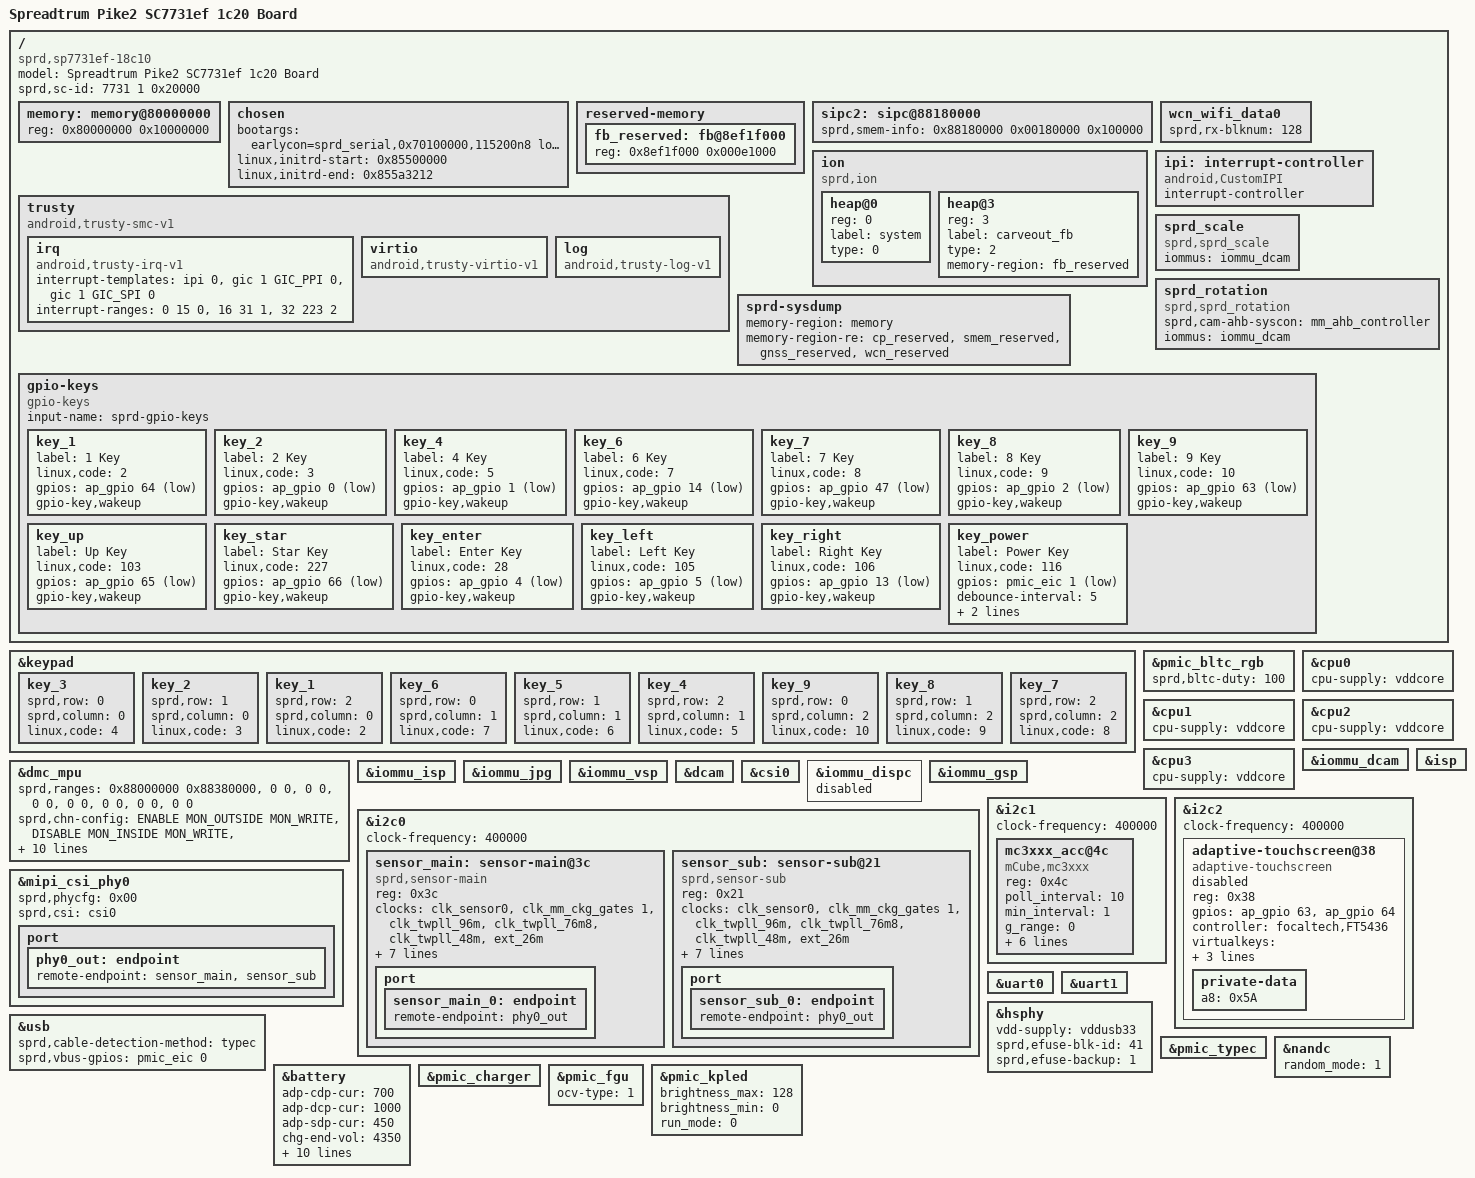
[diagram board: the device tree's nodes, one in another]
/*
 * Spreadtrum Pike2 SP7731ef DTS file
 *
 * Copyright (C) 2016-2017, Spreadtrum Communications Inc.
 *
 * This file is licensed under a dual GPLv2 or X11 license.
 */

#include "sc7731e.dtsi"
#include "sp7731ef-common.dtsi"

/ {
	model = "Spreadtrum Pike2 SC7731ef 1c20 Board";

	compatible = "sprd,sp7731ef-18c10", "sprd,sc7731e";

	sprd,sc-id = <7731 1 0x20000>;

	memory: memory@80000000 {
		device_type = "memory";
		reg = <0x80000000 0x10000000>;
	};

	chosen {
		bootargs = "earlycon=sprd_serial,0x70100000,115200n8 loglevel=1 console=ttyS1,115200n8 init=/init root=/dev/ram0 rw androidboot.hardware=sp7731ef_18c10";
		linux,initrd-start = <0x85500000>;
		linux,initrd-end = <0x855a3212>;
	};

	reserved-memory {
		#address-cells = <1>;
		#size-cells = <1>;
		ranges;

		fb_reserved: fb@8ef1f000{
			reg = <0x8ef1f000 0x000e1000>;
		};
	};

	sipc2: sipc@88180000 {
		/* <ap-addr dst-maped-addr size> */
		sprd,smem-info = <0x88180000 0x00180000 0x100000>;
	};

	wcn_wifi_data0 {
		sprd,rx-blknum = <128>;
	};

	ion {
		compatible = "sprd,ion";
		#address-cells = <1>;
		#size-cells = <0>;

		heap@0 {
			reg = <0>;
			label = "system";
			type = <0>;
		};

		heap@3 {
			reg = <3>;
			label = "carveout_fb";
			type = <2>;
			memory-region = <&fb_reserved>;
		};
	};

	ipi: interrupt-controller {
		compatible = "android,CustomIPI";
		#interrupt-cells = <1>;
		interrupt-controller;
	};

	trusty {
		compatible = "android,trusty-smc-v1";

		irq {
			compatible = "android,trusty-irq-v1";
			interrupt-templates = <&ipi 0>,
						<&gic 1 GIC_PPI 0>,
						<&gic 1 GIC_SPI 0>;
			interrupt-ranges = < 0  15 0>,
						<16  31 1>,
						<32 223 2>;
		};

		virtio {
			compatible = "android,trusty-virtio-v1";
		};

		log {
			compatible = "android,trusty-log-v1";
		};
	};

	sprd-sysdump {
		memory-region = <&memory>;
		memory-region-re = <&cp_reserved>, <&smem_reserved>,
				<&gnss_reserved>, <&wcn_reserved>;
	};

	sprd_scale {
		compatible = "sprd,sprd_scale";
		iommus = <&iommu_dcam>;
		status = "okay";
	};

	sprd_rotation {
		compatible = "sprd,sprd_rotation";
		sprd,cam-ahb-syscon = <&mm_ahb_controller>;
		iommus = <&iommu_dcam>;
		status = "okay";
	};

	gpio-keys {
		compatible = "gpio-keys";
		input-name = "sprd-gpio-keys";
		status = "okay";

		key_1 {
			label = "1 Key";
			linux,code = <2>;
			gpios = <&ap_gpio 64 1>;
			gpio-key,wakeup;
		};
		key_2 {
			label = "2 Key";
			linux,code = <3>;
			gpios = <&ap_gpio 0 1>;
			gpio-key,wakeup;
		};
		key_4 {
			label = "4 Key";
			linux,code = <5>;
			gpios = <&ap_gpio 1 1>;
			gpio-key,wakeup;
		};
		key_6 {
			label = "6 Key";
			linux,code = <7>;
			gpios = <&ap_gpio 14 1>;
			gpio-key,wakeup;
		};
		key_7 {
			label = "7 Key";
			linux,code = <8>;
			gpios = <&ap_gpio 47 1>;
			gpio-key,wakeup;
		};
		key_8 {
			label = "8 Key";
			linux,code = <9>;
			gpios = <&ap_gpio 2 1>;
			gpio-key,wakeup;
		};
		key_9 {
			label = "9 Key";
			linux,code = <10>;
			gpios = <&ap_gpio 63 1>;
			gpio-key,wakeup;
		};
		key_up {
			label = "Up Key";
			linux,code = <103>;
			gpios = <&ap_gpio 65 1>;
			gpio-key,wakeup;
		};
		key_star {
			label = "Star Key";
			linux,code = <227>;
			gpios = <&ap_gpio 66 1>;
			gpio-key,wakeup;
		};
		key_enter {
			label = "Enter Key";
			linux,code = <28>;
			gpios = <&ap_gpio 4 1>;
			gpio-key,wakeup;
		};
		key_left {
			label = "Left Key";
			linux,code = <105>;
			gpios = <&ap_gpio 5 1>;
			gpio-key,wakeup;
		};
		key_right {
			label = "Right Key";
			linux,code = <106>;
			gpios = <&ap_gpio 13 1>;
			gpio-key,wakeup;
		};
		key_power {
			label = "Power Key";
			linux,code = <116>;
			gpios = <&pmic_eic 1 1>;
			debounce-interval = <5>;
			gpio-key,wakeup;
			gpio-key,level-trigger;
		};
	};
};

&keypad {
	status = "okay";
	key_3 {
		sprd,row = <0>;
		sprd,column = <0>;
		linux,code = <4>;
	};
	key_2 {
		sprd,row = <1>;
		sprd,column = <0>;
		linux,code = <3>;
	};
	key_1 {
		sprd,row = <2>;
		sprd,column = <0>;
		linux,code = <2>;
	};
	key_6 {
		sprd,row = <0>;
		sprd,column = <1>;
		linux,code = <7>;
	};
	key_5 {
		sprd,row = <1>;
		sprd,column = <1>;
		linux,code = <6>;
	};
	key_4 {
		sprd,row = <2>;
		sprd,column = <1>;
		linux,code = <5>;
	};
	key_9 {
		sprd,row = <0>;
		sprd,column = <2>;
		linux,code = <10>;
	};
	key_8 {
		sprd,row = <1>;
		sprd,column = <2>;
		linux,code = <9>;
	};
	key_7 {
		sprd,row = <2>;
		sprd,column = <2>;
		linux,code = <8>;
	};
};

&pmic_bltc_rgb {
	sprd,bltc-duty = <100>;
	status = "okay";
};

/*
&lcd_ili9881c_3lane_mipi_hd {
	low-res-simu = <1>;
	simu-width = <240>;
	simu-height = <320>;
};*/

&cpu0 {
	cpu-supply = <&vddcore>;
};
&cpu1 {
	cpu-supply = <&vddcore>;
};
&cpu2 {
	cpu-supply = <&vddcore>;
};
&cpu3 {
	cpu-supply = <&vddcore>;
};

&dmc_mpu {
	status = "okay";
	sprd,ranges = <0x88000000 0x88380000>,
		      <0 0>,
		      <0 0>,
		      <0 0>,
		      <0 0>,
		      <0 0>,
		      <0 0>,
		      <0 0>;
	sprd,chn-config =
			<ENABLE MON_OUTSIDE MON_WRITE>,
			<DISABLE MON_INSIDE MON_WRITE>,
			<DISABLE MON_INSIDE MON_WRITE>,
			<DISABLE MON_INSIDE MON_WRITE>,
			<DISABLE MON_INSIDE MON_WRITE>,
			<DISABLE MON_INSIDE MON_WRITE>,
			<DISABLE MON_INSIDE MON_WRITE>,
			<DISABLE MON_INSIDE MON_WRITE>;
	sprd,id-config =
			<USERID 0xc0 0xc0>, <MPUID 0 0>,
			<MPUID 0 0>, <MPUID 0 0>,
			<MPUID 0 0>, <MPUID 0 0>,
			<MPUID 0 0>, <MPUID 0 0>;
	sprd,panic;
};

&iommu_dcam {
	status = "okay";
};

&iommu_isp {
	status = "okay";
};

&iommu_jpg {
	status = "okay";
};

&iommu_vsp {
	status = "okay";
};

&dcam {
	status = "okay";
};

&isp {
	status = "okay";
};

&csi0 {
	status = "okay";
};

&iommu_dispc {
	status = "disabled";
};

&iommu_gsp {
	status = "okay";
};

&i2c0 {
	status = "okay";
	clock-frequency = <400000>;

	sensor_main: sensor-main@3c {
		compatible = "sprd,sensor-main";
		reg = <0x3c>;
		clock-names = "clk_src", "sensor_eb",
			"clk_96m", "clk_76m8",
			"clk_48m", "clk_26m";
		clocks  = <&clk_sensor0>,
			<&clk_mm_ckg_gates 1>,
			<&clk_twpll_96m>,
			<&clk_twpll_76m8>,
			<&clk_twpll_48m>,
			<&ext_26m>;
		vddio-supply = <&vddcamio>;
		vddcama-supply = <&vddcama>;
		vddcamd-supply = <&vddcamd>;
		vddcammot-supply = <&vddcammot>;
		reset-gpios = <&ap_gpio 37 0>;
		power-down-gpios = <&ap_gpio 38 0>;
		host = "dcam0";
		port {
			sensor_main_0: endpoint {
				remote-endpoint = <&phy0_out>;
			};
		};
	};

	sensor_sub: sensor-sub@21 {
		compatible = "sprd,sensor-sub";
		reg = <0x21>;
		clock-names = "clk_src","sensor_eb",
			"clk_96m", "clk_76m8",
			"clk_48m", "clk_26m";
		clocks = <&clk_sensor0>,
			<&clk_mm_ckg_gates 1>,
			<&clk_twpll_96m>,
			<&clk_twpll_76m8>,
			<&clk_twpll_48m>,
			<&ext_26m>;
		vddio-supply = <&vddcamio>;
		vddcama-supply = <&vddcama>;
		vddcamd-supply = <&vddcamd>;
		vddcammot-supply = <&vddcammot>;
		reset-gpios = <&ap_gpio 46 0>;
		power-down-gpios = <&ap_gpio 39 0>;
		host = "dcam0";
		port {
			sensor_sub_0: endpoint {
				remote-endpoint = <&phy0_out>;
			};
		};
	};
};

&i2c1 {
	status = "okay";
	clock-frequency = <400000>;
	
	mc3xxx_acc@4c{
		compatible = "mCube,mc3xxx";
		reg = <0x4c>;
		poll_interval = <10>;
		min_interval = <1>;
		g_range = <0>;
		axis_maps_x = <0>;
		axis_maps_y = <1>;
		axis_maps_z = <2>;
		negate_x = <1>;
		negate_y = <1>;
		negate_z = <0>;
	};
};

&i2c2 {
	status = "okay";
	clock-frequency = <400000>;
	adaptive-touchscreen@38 {
		compatible = "adaptive-touchscreen";
		status = "disabled";
		reg = <0x38>;
		gpios = <&ap_gpio 63 0
			&ap_gpio 64 0>;
		controller = "focaltech,FT5436";
		virtualkeys = <580 60 1320 60 45
			172 360 1320 60 45
			158 600 1320 60 45>;
		surface-width = <240>;
		surface-height = <320>;
		private-data {
			a8 = /bits/ 8 <0x5A>;
		};
	};
};

&mipi_csi_phy0 {
	status = "okay";
	sprd,phycfg = <0x00>;
	sprd,csi = <&csi0>;
	port {
		phy0_out: endpoint {
			remote-endpoint = <&sensor_main>,<&sensor_sub>;
		};
	};
};

&uart0 {
	status = "okay";
};

&uart1 {
	status = "okay";
};

&hsphy {
	vdd-supply = <&vddusb33>;
	sprd,efuse-blk-id = <41>;
	sprd,efuse-backup = <1>;
};

&usb {
	sprd,cable-detection-method = "typec";
	sprd,vbus-gpios = <&pmic_eic 0 0>;
};

&pmic_typec {
	status = "okay";
};

&nandc {
	random_mode = <1>;
	status = "okay";
};

&battery {
	adp-cdp-cur = <700>;
	adp-dcp-cur = <1000>;
	adp-sdp-cur = <450>;
	chg-end-vol = <4350>;
	chg-end-vol-check = <4330>;
	chg-bat-safety-vol = <4430>;
	rechg-vol = <4270>;
	rsense-real = <200>;
	rint = <320>;
	cnom = <2780>;
	ocv-tab-vol = <4340 4243 4185 4132 4083 4037 3996
			3959 3921 3876 3842 3818 3800 3786
			3776 3768 3753 3731 3696 3663 3400>;
	ocv-tab-cap = <100  95   90   85   80   75   70
			65   60   55   50   45   40   35
			30   25   20   15   10   5    0>;
};

&pmic_charger {
	status = "okay";
};

&pmic_fgu {
	ocv-type = <1>;
};

&pmic_kpled {
	brightness_max = <128>;
	brightness_min = <0>;
	run_mode = <0>;
	status = "okay";
};
